# YTM32B1LE1 register map
Vendor: YTMicro; File version: 1.0
CPU: CM0PLUS r0p1, little endian, MPU, FPU, 2 interrupt priority bits
Registers are 32-bit, read-write, reset 0x0 unless marked. A register's access mark holds for its fields unless they carry their own. Offsets are from the block's base; [hi:lo] are bit positions; {n}, {i} and the like mark numbered series.

## WDG0 — Watchdog module
Base 0x40052000; register names take the prefix WDG0_
0x00 SVCR wo — Watchdog Service Code Register
  [15:0] SVCODE — It can be used to service the watchdog or to clear the soft lock bit. Writing 0xB631 followed by 0xC278 will clear the soft lock bit, writing 0xA518 followed by 0xD826 to service the watchdog.
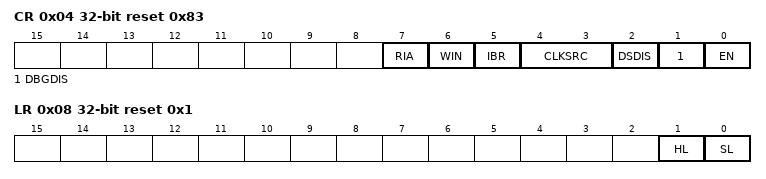
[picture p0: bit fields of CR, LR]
0x04 CR reset 0x83 — Watchdog Control Register
  [7] RIA — Enable reset for invalid APB access.
    0=Generate bus error on invalid APB access; 1=Generate bus error and system reset on invalid APB access
  [6] WIN — Enable window mode.
    0=Disable window mode, watchdog service can be done at any time; 1=Enable window mode, watchdog service is can only be done when timer value is less than the value of WIN register
  [5] IBR — Enable interrupt before reset function
    0=Disable interrupt before reset; 1=Enable interrupt before reset, when watchdog time-out, generate an interrupt first and when next time-out happens, generate reset
  [4:3] CLKSRC
    0=LPO_CLK; 1=SIRC; 3=wdg bus clk
  [2] DSDIS — Enable or disable watchdog in deepsleep mode. For detailed information, refer to \hyperref[operation-modes]{Operation Modes}.
    0=Enable watchdog in deepsleep mode; 1=Disable watchdog in deepsleep mode
  [1] DBGDIS — Enable or disable watchdog in debug mode.
    0=Enable watchdog in debug mode; 1=Disable watchdog in debug mode
  [0] EN — Enable watchdog module.
    0=Disable watchdog module; 1=Enable watchdog module
0x08 LR reset 0x1 — Watchdog Lock Register
  [1] HL — Hard lock, when this bit set, the CR, WIN, TOVR are read-only. once set, the bit can only be clear by reset.
  [0] SL — Soft lock, when this bit set, the CR, WIN, TOVR are read-only. this bit can be clear by writing a valid sequence to SVCR register.
0x0C TOVR reset 0xC00 — Watchdog Timer Overflow Value
  [15:0] TO — A 16bit down counter uses this value to start count. This register can be configured by byte,so too small value should not configure to this register,preferably not less than the reset value.
0x10 WVR
  [15:0] WIN — When CR[WIN] is set, the window mode is enabled, the service sequence can only be written when the timer value is less than the value of this register.
0x14 CNTCVR ro — Watchdog Counter Current Value Register
  [15:0] CVAL
0x18 INTF — Watchdog Interrupt Flag register
  [0] IF — Watchdog interrupt flag. Write 1 to this field to clear the flag and interrupt.
    0=No watchdog interrupt is pending; 1=Watchdog timer time-out interrupt is pending

## CFMU0 — Clock frequency measure unit
Base 0x40077000; register names take the prefix CFMU0_
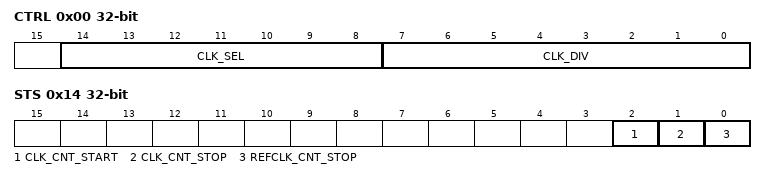
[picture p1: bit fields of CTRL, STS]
0x00 CTRL
  [14:8] CLK_SEL — These bits control the source selection of to-be-measured clock. ewline This register bit is reset by Power-on Reset.
    1=FIRC clock; 2=SIRC clock; 3=FXOSC clock; 5=LPO clock; 7=Core clock
  [7:0] CLK_DIV — These bits control the divider of the to-be-measured clock. The divisor is (CLK_DIV + 1). Note CLK_DIV can only be modified when CLK_SEL is 0. This register bit is reset by Power-on Reset.
0x04 CLK_CNT — The count of to-be-measured clock.
  [15:0] CNT — Read this register to get the current value of to-be-measured clock counter. Writing to this register with any value will enable both the reference clock counter and to-be-measured clock counter.
0x08 REFCLK_CNT — The count of reference clock.
  [15:0] CNT — Read this register to get the current reference clock counter value. Writing to this register with any value will clear both the reference clock counter and to-be-measured clock counter.
0x0C CLK_TGTCNT reset 0xFFFF
  [15:0] CNT — Target count for the to-be-measured clock.
0x10 REFCLK_TGTCNT reset 0xFFFF
  [15:0] CNT — Target count for the reference clock.
0x14 STS ro
  [2] CLK_CNT_START — The to-be-measured clock count starts or not. The counter starts when CLK_CNT has been written.
    0=The to-be-measured clock count doesn't start; 1=The to-be-measured clock count starts
  [1] CLK_CNT_STOP — The to-be-measured clock count stops or not. The counter stops when it reaches the value configured in CLK_TGTCNT.
    0=The to-be-measured clock count doesn't stop; 1=The to-be-measured clock count stops
  [0] REFCLK_CNT_STOP — Reference clock count stops or not. The counter stops when it reaches the value configured in REFCLK_TGTCNT.
    0=Reference clock count doesn't stop; 1=Reference clock count stops
0x18 REFCLK_CNT_SAVED ro
  [15:0] CNT — Reference clock count is saved when CUT counter starts or stops.
